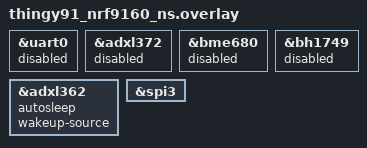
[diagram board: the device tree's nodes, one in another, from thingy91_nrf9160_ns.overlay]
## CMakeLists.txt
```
#
# Copyright (c) 2021 Nordic Semiconductor
#
# SPDX-License-Identifier: LicenseRef-Nordic-5-Clause
#

cmake_minimum_required(VERSION 3.20.0)

find_package(Zephyr REQUIRED HINTS $ENV{ZEPHYR_BASE})
project(TrashCanMonitor)

# NORDIC SDK APP START
target_sources(app PRIVATE src/sms.c)
target_sources(app PRIVATE src/accel.c)
target_sources(app PRIVATE src/battery.c)
# NORDIC SDK APP END
```

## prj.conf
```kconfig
#
# Copyright (c) 2021 Nordic Semiconductor ASA
#
# SPDX-License-Identifier: LicenseRef-Nordic-5-Clause
#
# General config

CONFIG_SMS_SEND_PHONE_NUMBER="16786441818"

CONFIG_SMS=y
CONFIG_SMS_SUBSCRIBERS_MAX_CNT=2
CONFIG_SMS_LOG_LEVEL_DBG=n
CONFIG_MAIN_STACK_SIZE=1536

# Networking
CONFIG_NETWORKING=y
CONFIG_NET_SOCKETS=y
CONFIG_NET_SOCKETS_OFFLOAD=y
CONFIG_NRF_MODEM_LIB=y
CONFIG_POSIX_API=y

# LTE link control
CONFIG_LTE_LINK_CONTROL=y
CONFIG_LTE_NETWORK_USE_FALLBACK=n

# Debugging
CONFIG_LOG=y
CONFIG_ASSERT=y
CONFIG_ASSERT_VERBOSE=y

CONFIG_SERIAL=n
CONFIG_UART_CONSOLE=n
CONFIG_RTT_CONSOLE=y
CONFIG_USE_SEGGER_RTT=y

# Power management
#CONFIG_LTE_EDRX_REQ=y
#CONFIG_LTE_PSM_REQ=y
CONFIG_DATE_TIME=y
CONFIG_DATE_TIME_NTP=y
CONFIG_DATE_TIME_AUTO_UPDATE=y

CONFIG_SENSOR=y
CONFIG_SPI=y
CONFIG_ADXL362_TRIGGER_OWN_THREAD=y
CONFIG_ADXL362_ACCEL_ODR_12_5=y
CONFIG_ADXL362_INTERRUPT_MODE=1
CONFIG_ADXL362_ABS_REF_MODE=1
CONFIG_ADXL362_INACTIVITY_TIME=13

CONFIG_FPU=y
CONFIG_CBPRINTF_FP_SUPPORT=y

CONFIG_I2C=y
CONFIG_FUEL_GAUGE=y

CONFIG_PM_DEVICE=y
```

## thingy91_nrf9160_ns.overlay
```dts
&uart0 {
    status = "disabled";
};

&adxl372 {
    status = "disabled";
};

&bme680 {
    status = "disabled";
};

&bh1749 {
    status = "disabled";
};

&adxl362 {
    status = "okay";
    autosleep;
    wakeup-source;
};

&spi3 {
    status = "okay";
};
```

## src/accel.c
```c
#include <zephyr/kernel.h>
#include <zephyr/logging/log.h>
#include <zephyr/drivers/sensor.h>
#include <modem/sms.h>
#include <math.h>

LOG_MODULE_REGISTER(accel, CONFIG_LOG_DEFAULT_LEVEL);

const struct device *const accel_dev = DEVICE_DT_GET_ONE(adi_adxl362);

static struct sensor_trigger accel_trigger;

extern struct k_mutex sms_mutex;

static void trigger_handler(const struct device *dev, const struct sensor_trigger *trig) {
    struct sensor_value accel[3];

    int ret;

    ret = sensor_sample_fetch(dev);
    if (ret < 0) {
        LOG_ERR("sensor_sample_fetch failed ret %d", ret);
        return;
    }

    for (int i = 0; i < 3; i++) {
        ret = sensor_channel_get(dev, SENSOR_CHAN_ACCEL_X + i, &accel[i]);
        if (ret < 0) {
            LOG_ERR("sensor_channel_get failed ret %d", ret);
            return;
        }
    }
    // Convert to polar coordinates
    float x = sensor_value_to_double(&accel[0]);
    float y = sensor_value_to_double(&accel[1]);
    float z = sensor_value_to_double(&accel[2]);

    float a = sqrt(x * x + y * y + z * z);
    float inc_x = asin(x / a);
    float inc_y = asin(y / a);
    float inc_z = atan2(y, x);

    // Conver to degrees
    inc_x = inc_x * 180 / 3.1415;
    inc_y = inc_y * 180 / 3.1415;
    inc_z = inc_z * 180 / 3.1415;

    LOG_INF("Acceleration: x=%f y=%f z=%f", x, y, z);
    LOG_INF("Polar coordinates: a=%f inc_x=%f inc_y=%f inc_z=%f", a, inc_x, inc_y, inc_z);
    if (inc_y < 0) {
        ret = sms_send_text(CONFIG_SMS_SEND_PHONE_NUMBER, "PICKED UP");
        if (ret) { 
            LOG_ERR("Sending SMS failed with error: %d\n", ret);
        }
    }
    else if (inc_y > 95) {
        // Send a ZBUS message to calendar.c
    }
}

static int accel_thread(void) {
    int ret;

    if (!device_is_ready(accel_dev)) {
        LOG_ERR("ADXL362 device is not ready");
        return -ENODEV;
    }

    accel_trigger.type = SENSOR_TRIG_MOTION;
    accel_trigger.chan = SENSOR_CHAN_ACCEL_XYZ;

    ret = sensor_trigger_set(accel_dev, &accel_trigger, trigger_handler);
    if (ret < 0) {
        LOG_ERR("sensor_trigger_set failed ret %d", ret);
        return ret;
    }

    return 0;
}

K_THREAD_DEFINE(accel_thread_id, 1024, accel_thread, NULL, NULL, NULL, 10, 0, 0);
```

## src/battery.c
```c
#include <stdio.h>
#include <zephyr/init.h>
#include <zephyr/kernel.h>
#include <zephyr/logging/log.h>
#include <modem/sms.h>
#include <adp536x.h>

LOG_MODULE_REGISTER(battery, CONFIG_LOG_DEFAULT_LEVEL);

static void battery_charge_work_handler(struct k_work *work) {
    int ret;

    uint8_t percentage;
    adp536x_fg_soc(&percentage);
    LOG_INF("Battery percentage: %d", percentage);

    if (percentage < 20) {
        ret = sms_send_text(CONFIG_SMS_SEND_PHONE_NUMBER, "BATTERY LOW");
        if (ret) { 
            LOG_ERR("Sending SMS failed with error: %d\n", ret);
        }
    }
}

K_WORK_DEFINE(battery_work, battery_charge_work_handler);

static void battery_charge_handler(struct k_timer *timer) {
    k_work_submit(&battery_work);
}

K_TIMER_DEFINE(battery_timer, battery_charge_handler, NULL);

int battery_timer_init(void) {

    k_work_submit(&battery_work);

    k_timer_start(&battery_timer, K_SECONDS(3600), K_SECONDS(3600));
    LOG_INF("Battery timer started");
    return 0;
}

SYS_INIT(battery_timer_init, APPLICATION, CONFIG_APPLICATION_INIT_PRIORITY);
```

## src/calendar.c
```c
#include <stdio.h>
#include <zephyr/kernel.h>
#include <zephyr/init.h>
#include <zephyr/logging/log.h>
#include <zephyr/posix/time.h>
#include <modem/sms.h>

LOG_MODULE_REGISTER(calendar, CONFIG_LOG_DEFAULT_LEVEL);

volatile static bool moved_this_week = false;

static int get_day_of_week(void) {
    struct timespec tp;
    struct tm ts;
    clock_gettime(CLOCK_REALTIME, &tp);

    ts = *localtime(&tp.tv_sec);

    return ts.tm_wday;
}

static void battery_charge_work_handler(struct k_work *work) {
    int ret;

    int day_of_week = get_day_of_week();
    if (day_of_week == 2)
}

K_WORK_DEFINE(battery_work, battery_charge_work_handler);

static void battery_charge_handler(struct k_timer *timer) {
    k_work_submit(&battery_work);
}

K_TIMER_DEFINE(battery_timer, battery_charge_handler, NULL);

int battery_timer_init(void) {

    k_work_submit(&battery_work);

    k_timer_start(&battery_timer, K_SECONDS(3600), K_SECONDS(3600));
    LOG_INF("Battery timer started");
    return 0;
}

SYS_INIT(battery_timer_init, APPLICATION, CONFIG_APPLICATION_INIT_PRIORITY);
```

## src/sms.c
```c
#include <zephyr/init.h>
#include <zephyr/kernel.h>
#include <zephyr/logging/log.h>
#include <modem/sms.h>
#include <modem/nrf_modem_lib.h>
#include <modem/lte_lc.h>

LOG_MODULE_REGISTER(sms_init, CONFIG_LOG_DEFAULT_LEVEL);

static void sms_callback(struct sms_data *const data, void *context)
{
	if (data == NULL) {
		LOG_ERR("%s with NULL data\n", __func__);
		return;
	}

	if (data->type == SMS_TYPE_STATUS_REPORT) {
		LOG_INF("SMS status report received\n");
	} else {
		LOG_ERR("SMS protocol message with unknown type received\n");
	}
}

int sms_init(void) {
	int ret = 0;
	int handle = 0;

	LOG_INF("Oscar Online");

	ret = nrf_modem_lib_init();
	if (ret) {
		LOG_ERR("Modem library initialization failed, error: %d\n", ret);
		return 0;
	}

	ret = lte_lc_init_and_connect();
	if (ret) {
		LOG_ERR("Lte_lc failed to initialize and connect, err %d", ret);
		return 0;
	}

	handle = sms_register_listener(sms_callback, NULL);
	if (handle) {
		LOG_ERR("sms_register_listener returned err: %d\n", handle);
		return 0;
	}

	return 0;
}

SYS_INIT(sms_init, APPLICATION, CONFIG_APPLICATION_INIT_PRIORITY);
```
